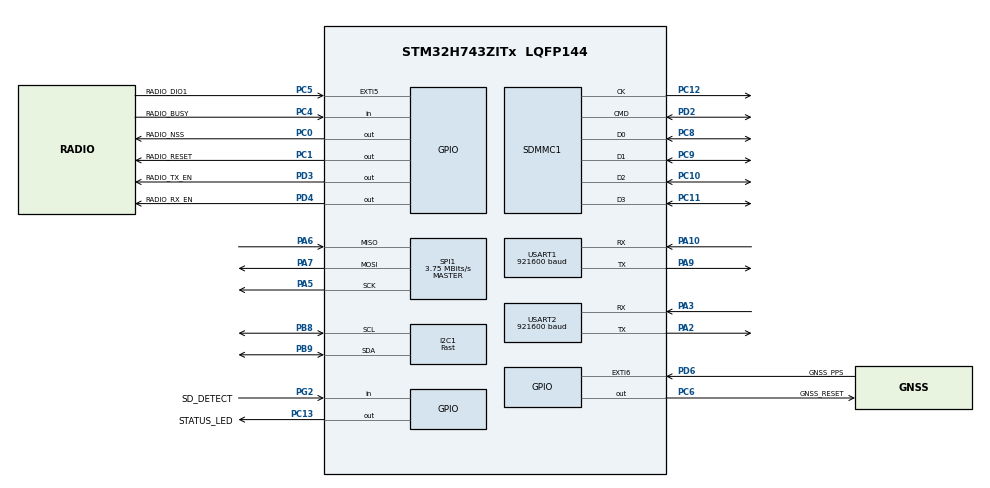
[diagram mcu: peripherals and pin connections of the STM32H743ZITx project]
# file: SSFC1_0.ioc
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CORTEX_M7.default_mode_Activation=1
Dma.Request0=USART1_RX
Dma.Request1=USART1_TX
Dma.Request2=USART2_RX
Dma.Request3=USART2_TX
Dma.USART1_RX.0.Direction=DMA_PERIPH_TO_MEMORY
Dma.USART1_RX.0.EventEnable=DISABLE
Dma.USART1_RX.0.FIFOMode=DMA_FIFOMODE_DISABLE
Dma.USART1_RX.0.Instance=DMA1_Stream0
Dma.USART1_RX.0.MemDataAlignment=DMA_MDATAALIGN_BYTE
Dma.USART1_RX.0.MemInc=DMA_MINC_ENABLE
Dma.USART1_RX.0.Mode=DMA_CIRCULAR
Dma.USART1_RX.0.PeriphDataAlignment=DMA_PDATAALIGN_BYTE
Dma.USART1_RX.0.PeriphInc=DMA_PINC_DISABLE
Dma.USART1_RX.0.Polarity=HAL_DMAMUX_REQ_GEN_RISING
Dma.USART1_RX.0.Priority=DMA_PRIORITY_HIGH
Dma.USART1_RX.0.RequestNumber=1
Dma.USART1_RX.0.SignalID=NONE
Dma.USART1_RX.0.SyncEnable=DISABLE
Dma.USART1_RX.0.SyncPolarity=HAL_DMAMUX_SYNC_NO_EVENT
Dma.USART1_RX.0.SyncRequestNumber=1
Dma.USART1_RX.0.SyncSignalID=NONE
Dma.USART1_TX.1.Direction=DMA_MEMORY_TO_PERIPH
Dma.USART1_TX.1.EventEnable=DISABLE
Dma.USART1_TX.1.FIFOMode=DMA_FIFOMODE_DISABLE
Dma.USART1_TX.1.Instance=DMA1_Stream1
Dma.USART1_TX.1.MemDataAlignment=DMA_MDATAALIGN_BYTE
Dma.USART1_TX.1.MemInc=DMA_MINC_ENABLE
Dma.USART1_TX.1.Mode=DMA_NORMAL
Dma.USART1_TX.1.PeriphDataAlignment=DMA_PDATAALIGN_BYTE
Dma.USART1_TX.1.PeriphInc=DMA_PINC_DISABLE
Dma.USART1_TX.1.Polarity=HAL_DMAMUX_REQ_GEN_RISING
Dma.USART1_TX.1.Priority=DMA_PRIORITY_HIGH
Dma.USART1_TX.1.RequestNumber=1
Dma.USART1_TX.1.SignalID=NONE
Dma.USART1_TX.1.SyncEnable=DISABLE
Dma.USART1_TX.1.SyncPolarity=HAL_DMAMUX_SYNC_NO_EVENT
Dma.USART1_TX.1.SyncRequestNumber=1
Dma.USART1_TX.1.SyncSignalID=NONE
Dma.USART2_RX.2.Direction=DMA_PERIPH_TO_MEMORY
Dma.USART2_RX.2.EventEnable=DISABLE
Dma.USART2_RX.2.FIFOMode=DMA_FIFOMODE_DISABLE
Dma.USART2_RX.2.Instance=DMA1_Stream2
Dma.USART2_RX.2.MemDataAlignment=DMA_MDATAALIGN_BYTE
Dma.USART2_RX.2.MemInc=DMA_MINC_ENABLE
Dma.USART2_RX.2.Mode=DMA_CIRCULAR
Dma.USART2_RX.2.PeriphDataAlignment=DMA_PDATAALIGN_BYTE
Dma.USART2_RX.2.PeriphInc=DMA_PINC_DISABLE
Dma.USART2_RX.2.Polarity=HAL_DMAMUX_REQ_GEN_RISING
Dma.USART2_RX.2.Priority=DMA_PRIORITY_HIGH
Dma.USART2_RX.2.RequestNumber=1
Dma.USART2_RX.2.SignalID=NONE
Dma.USART2_RX.2.SyncEnable=DISABLE
Dma.USART2_RX.2.SyncPolarity=HAL_DMAMUX_SYNC_NO_EVENT
Dma.USART2_RX.2.SyncRequestNumber=1
Dma.USART2_RX.2.SyncSignalID=NONE
Dma.USART2_TX.3.Direction=DMA_MEMORY_TO_PERIPH
Dma.USART2_TX.3.EventEnable=DISABLE
Dma.USART2_TX.3.FIFOMode=DMA_FIFOMODE_DISABLE
Dma.USART2_TX.3.Instance=DMA1_Stream3
Dma.USART2_TX.3.MemDataAlignment=DMA_MDATAALIGN_BYTE
Dma.USART2_TX.3.MemInc=DMA_MINC_ENABLE
Dma.USART2_TX.3.Mode=DMA_NORMAL
Dma.USART2_TX.3.PeriphDataAlignment=DMA_PDATAALIGN_BYTE
Dma.USART2_TX.3.PeriphInc=DMA_PINC_DISABLE
Dma.USART2_TX.3.Polarity=HAL_DMAMUX_REQ_GEN_RISING
Dma.USART2_TX.3.Priority=DMA_PRIORITY_HIGH
Dma.USART2_TX.3.RequestNumber=1
Dma.USART2_TX.3.SignalID=NONE
Dma.USART2_TX.3.SyncEnable=DISABLE
Dma.USART2_TX.3.SyncPolarity=HAL_DMAMUX_SYNC_NO_EVENT
Dma.USART2_TX.3.SyncRequestNumber=1
Dma.USART2_TX.3.SyncSignalID=NONE
FATFS.BSP.number=1
FATFS._CODE_PAGE=437
FATFS._USE_LFN=2
FATFS0.BSP.STBoard=false
FATFS0.BSP.api=Unknown
FATFS0.BSP.instance=PG2
FATFS0.BSP.ip=GPIO
FATFS0.BSP.mode=Input
FATFS0.BSP.name=Detect_SDIO
FATFS0.BSP.solution=PG2
I2C1.I2C_Speed_Mode=I2C_Fast
I2C1.Timing=0x307075B1
Mcu.Family=STM32H7
Mcu.Name=STM32H743ZITx
Mcu.Package=LQFP144
NVIC.DMA1_Stream0_IRQn=true\:5\:0\:false\:false\:true\:false\:true\:true
NVIC.DMA1_Stream1_IRQn=true\:5\:0\:false\:false\:true\:false\:true\:true
NVIC.DMA1_Stream2_IRQn=true\:5\:0\:false\:false\:true\:false\:true\:true
NVIC.DMA1_Stream3_IRQn=true\:5\:0\:false\:false\:true\:false\:true\:true
NVIC.EXTI9_5_IRQn=true\:5\:0\:false\:false\:true\:true\:true\:true
NVIC.PriorityGroup=NVIC_PRIORITYGROUP_4
NVIC.SDMMC1_IRQn=true\:5\:0\:false\:false\:true\:true\:true\:true
NVIC.TIM6_DAC_IRQn=true\:15\:0\:false\:false\:true\:false\:false\:true
NVIC.TimeBase=TIM6_DAC_IRQn
NVIC.TimeBaseIP=TIM6
NVIC.USART1_IRQn=true\:5\:0\:false\:false\:true\:true\:true\:true
NVIC.USART2_IRQn=true\:5\:0\:false\:false\:true\:true\:true\:true
PA10.Mode=Asynchronous
PA10.Signal=USART1_RX
PA13\ (JTMS/SWDIO).Mode=Serial_Wire
PA13\ (JTMS/SWDIO).Signal=DEBUG_JTMS-SWDIO
PA14\ (JTCK/SWCLK).Mode=Serial_Wire
PA14\ (JTCK/SWCLK).Signal=DEBUG_JTCK-SWCLK
PA2.Mode=Asynchronous
PA2.Signal=USART2_TX
PA3.Mode=Asynchronous
PA3.Signal=USART2_RX
PA5.Mode=Full_Duplex_Master
PA5.Signal=SPI1_SCK
PA6.Mode=Full_Duplex_Master
PA6.Signal=SPI1_MISO
PA7.Mode=Full_Duplex_Master
PA7.Signal=SPI1_MOSI
PA9.Mode=Asynchronous
PA9.Signal=USART1_TX
PB8.Mode=I2C
PB8.Signal=I2C1_SCL
PB9.Mode=I2C
PB9.Signal=I2C1_SDA
PC0.GPIO_Label=RADIO_NSS
PC0.PinState=GPIO_PIN_SET
PC0.Signal=GPIO_Output
PC1.GPIO_Label=RADIO_RESET
PC1.PinState=GPIO_PIN_SET
PC1.Signal=GPIO_Output
PC10.Mode=SD_4_bits_Wide_bus
PC10.Signal=SDMMC1_D2
PC11.Mode=SD_4_bits_Wide_bus
PC11.Signal=SDMMC1_D3
PC12.Mode=SD_4_bits_Wide_bus
PC12.Signal=SDMMC1_CK
PC13.GPIO_Label=STATUS_LED
PC13.Signal=GPIO_Output
PC4.GPIO_Label=RADIO_BUSY
PC4.Signal=GPIO_Input
PC5.GPIO_Label=RADIO_DIO1
PC5.GPIO_ModeDefaultEXTI=GPIO_MODE_IT_RISING
PC5.Signal=GPXTI5
PC6.GPIO_Label=GNSS_RESET
PC6.PinState=GPIO_PIN_SET
PC6.Signal=GPIO_Output
PC8.Mode=SD_4_bits_Wide_bus
PC8.Signal=SDMMC1_D0
PC9.Mode=SD_4_bits_Wide_bus
PC9.Signal=SDMMC1_D1
PD2.Mode=SD_4_bits_Wide_bus
PD2.Signal=SDMMC1_CMD
PD3.GPIO_Label=RADIO_TX_EN
PD3.Signal=GPIO_Output
PD4.GPIO_Label=RADIO_RX_EN
PD4.Signal=GPIO_Output
PD6.GPIO_Label=GNSS_PPS
PD6.GPIO_ModeDefaultEXTI=GPIO_MODE_IT_RISING
PD6.Signal=GPXTI6
PG2.GPIO_Label=SD_DETECT
PG2.Signal=GPIO_Input
PH0-OSC_IN\ (PH0).Mode=HSE-External-Oscillator
PH0-OSC_IN\ (PH0).Signal=RCC_OSC_IN
PH1-OSC_OUT\ (PH1).Mode=HSE-External-Oscillator
PH1-OSC_OUT\ (PH1).Signal=RCC_OSC_OUT
ProjectManager.HeapSize=0x0
ProjectManager.StackSize=0x2000
ProjectManager.TargetToolchain=Makefile
RCC.ADCFreq_Value=50390625
RCC.APB1Freq_Value=120000000
RCC.APB2Freq_Value=120000000
RCC.APB3Freq_Value=120000000
RCC.APB4Freq_Value=120000000
RCC.CortexFreq_Value=480000000
RCC.D1CPRE=RCC_SYSCLK_DIV1
RCC.D1PPRE=RCC_APB3_DIV2
RCC.D2PPRE1=RCC_APB1_DIV2
RCC.D2PPRE2=RCC_APB2_DIV2
RCC.D3PPRE=RCC_APB4_DIV2
RCC.DIVM1=5
RCC.DIVN1=192
RCC.DIVP1=2
RCC.DIVQ1=8
RCC.DIVR1=2
RCC.HCLKFreq_Value=240000000
RCC.HPRE=RCC_HCLK_DIV2
RCC.HSE_VALUE=25000000
RCC.PLL1_VCI_Range=RCC_PLL1VCIRANGE_2
RCC.PLL1_VCO_SEL=RCC_PLL1VCOWIDE
RCC.PLLSourceVirtual=RCC_PLLSOURCE_HSE
RCC.PWR_Regulator_Voltage_Scale=PWR_REGULATOR_VOLTAGE_SCALE0
RCC.SYSCLKFreq_VALUE=480000000
RCC.SYSCLKSource=RCC_SYSCLKSOURCE_PLLCLK
RCC.USBFreq_Value=120000000
SDMMC1.ClockDiv=3
SPI1.BaudRatePrescaler=SPI_BAUDRATEPRESCALER_32
SPI1.CalculateBaudRate=3.75 MBits/s
SPI1.DataSize=SPI_DATASIZE_8BIT
SPI1.Direction=SPI_DIRECTION_2LINES
SPI1.Mode=SPI_MODE_MASTER
SPI1.VirtualType=VM_MASTER
USART1.BaudRate=921600
USART1.VirtualMode=VM_ASYNC
USART1.VirtualMode-Asynchronous=VM_ASYNC
USART1.WordLength=WORDLENGTH_8B
USART2.BaudRate=921600
USART2.VirtualMode=VM_ASYNC
USART2.VirtualMode-Asynchronous=VM_ASYNC
USART2.WordLength=WORDLENGTH_8B
VP_FATFS_VS_SDIO.Mode=SDIO
VP_MEMORYMAP_VS_MEMORYMAP.Mode=CurAppReg
VP_SYS_VS_tim6.Mode=TIM6
board=custom

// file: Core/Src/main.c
/* USER CODE BEGIN Header */
/**
  ******************************************************************************
  * @file           : main.c
  * @brief          : Main program body
  ******************************************************************************
  * @attention
  *
  * Copyright (c) 2026 STMicroelectronics.
  * All rights reserved.
  *
  * This software is licensed under terms that can be found in the LICENSE file
  * in the root directory of this software component.
  * If no LICENSE file comes with this software, it is provided AS-IS.
  *
  ******************************************************************************
  */
/* USER CODE END Header */
#include "main.h"
#include "dma.h"
#include "fatfs.h"
#include "i2c.h"
#include "sdmmc.h"
#include "spi.h"
#include "usart.h"
#include "gpio.h"

/* USER CODE BEGIN Includes */
#include "FreeRTOS.h"
#include "task.h"
#include "app_tasks.h"
#include "system_startup.h"
/* USER CODE END Includes */

void SystemClock_Config(void);
static void MPU_Config(void);

int main(void)
{

  /* MPU Configuration--------------------------------------------------------*/
  MPU_Config();

  /* MCU Configuration--------------------------------------------------------*/

  /* Reset of all peripherals, Initializes the Flash interface and the Systick. */
  HAL_Init();

  /* Configure the system clock */
  SystemClock_Config();

  /* Initialize all configured peripherals */
  MX_GPIO_Init();
  MX_DMA_Init();
  MX_I2C1_Init();
  MX_SDMMC1_SD_Init();
  MX_SPI1_Init();
  MX_USART1_UART_Init();
  MX_USART2_UART_Init();
  MX_FATFS_Init();
  /* USER CODE BEGIN 2 */
  {
    SystemStartupResult result = SystemStartup_Run();
    if (SystemStartup_ResultIsFatal(result) != 0U)
    {
      Error_Handler();
    }
  }
  if (AppTasks_Init() != AppTasksInitResult_Ok)
  {
    Error_Handler();
  }
  vTaskStartScheduler();
  Error_Handler();
/* USER CODE END 2 */

  /* Infinite loop */
  while (1)
  {

  }
}

void SystemClock_Config(void)
{
  RCC_OscInitTypeDef RCC_OscInitStruct = {0};
  RCC_ClkInitTypeDef RCC_ClkInitStruct = {0};

  /** Supply configuration update enable
  */
  HAL_PWREx_ConfigSupply(PWR_LDO_SUPPLY);

  /** Configure the main internal regulator output voltage
  */
  __HAL_PWR_VOLTAGESCALING_CONFIG(PWR_REGULATOR_VOLTAGE_SCALE0);

  while(!__HAL_PWR_GET_FLAG(PWR_FLAG_VOSRDY)) {}

  /** Initializes the RCC Oscillators according to the specified parameters
  * in the RCC_OscInitTypeDef structure.
  */
  RCC_OscInitStruct.OscillatorType = RCC_OSCILLATORTYPE_HSE;
  RCC_OscInitStruct.HSEState = RCC_HSE_ON;
  RCC_OscInitStruct.PLL.PLLState = RCC_PLL_ON;
  RCC_OscInitStruct.PLL.PLLSource = RCC_PLLSOURCE_HSE;
  RCC_OscInitStruct.PLL.PLLM = 5;
  RCC_OscInitStruct.PLL.PLLN = 192;
  RCC_OscInitStruct.PLL.PLLP = 2;
  RCC_OscInitStruct.PLL.PLLQ = 8;
  RCC_OscInitStruct.PLL.PLLR = 2;
  RCC_OscInitStruct.PLL.PLLRGE = RCC_PLL1VCIRANGE_2;
  RCC_OscInitStruct.PLL.PLLVCOSEL = RCC_PLL1VCOWIDE;
  RCC_OscInitStruct.PLL.PLLFRACN = 0;
  if (HAL_RCC_OscConfig(&RCC_OscInitStruct) != HAL_OK)
  {
    Error_Handler();
  }

  /** Initializes the CPU, AHB and APB buses clocks
  */
  RCC_ClkInitStruct.ClockType = RCC_CLOCKTYPE_HCLK|RCC_CLOCKTYPE_SYSCLK
                              |RCC_CLOCKTYPE_PCLK1|RCC_CLOCKTYPE_PCLK2
                              |RCC_CLOCKTYPE_D3PCLK1|RCC_CLOCKTYPE_D1PCLK1;
  RCC_ClkInitStruct.SYSCLKSource = RCC_SYSCLKSOURCE_PLLCLK;
  RCC_ClkInitStruct.SYSCLKDivider = RCC_SYSCLK_DIV1;
  RCC_ClkInitStruct.AHBCLKDivider = RCC_HCLK_DIV2;
  RCC_ClkInitStruct.APB3CLKDivider = RCC_APB3_DIV2;
  RCC_ClkInitStruct.APB1CLKDivider = RCC_APB1_DIV2;
  RCC_ClkInitStruct.APB2CLKDivider = RCC_APB2_DIV2;
  RCC_ClkInitStruct.APB4CLKDivider = RCC_APB4_DIV2;

  if (HAL_RCC_ClockConfig(&RCC_ClkInitStruct, FLASH_LATENCY_4) != HAL_OK)
  {
    Error_Handler();
  }
}

 /* MPU Configuration */

void MPU_Config(void)
{
  MPU_Region_InitTypeDef MPU_InitStruct = {0};

  /* Disables the MPU */
  HAL_MPU_Disable();

  /** Initializes and configures the Region and the memory to be protected
  */
  MPU_InitStruct.Enable = MPU_REGION_ENABLE;
  MPU_InitStruct.Number = MPU_REGION_NUMBER0;
  MPU_InitStruct.BaseAddress = 0x0;
  MPU_InitStruct.Size = MPU_REGION_SIZE_4GB;
  MPU_InitStruct.SubRegionDisable = 0x87;
  MPU_InitStruct.TypeExtField = MPU_TEX_LEVEL0;
  MPU_InitStruct.AccessPermission = MPU_REGION_NO_ACCESS;
  MPU_InitStruct.DisableExec = MPU_INSTRUCTION_ACCESS_DISABLE;
  MPU_InitStruct.IsShareable = MPU_ACCESS_SHAREABLE;
  MPU_InitStruct.IsCacheable = MPU_ACCESS_NOT_CACHEABLE;
  MPU_InitStruct.IsBufferable = MPU_ACCESS_NOT_BUFFERABLE;

  HAL_MPU_ConfigRegion(&MPU_InitStruct);
  /* Enables the MPU */
  HAL_MPU_Enable(MPU_PRIVILEGED_DEFAULT);

}

void HAL_TIM_PeriodElapsedCallback(TIM_HandleTypeDef *htim)
{
  if (htim->Instance == TIM6)
  {
    HAL_IncTick();
  }
}

void Error_Handler(void)
{
  __disable_irq();
  while (1)
  {
  }
}
